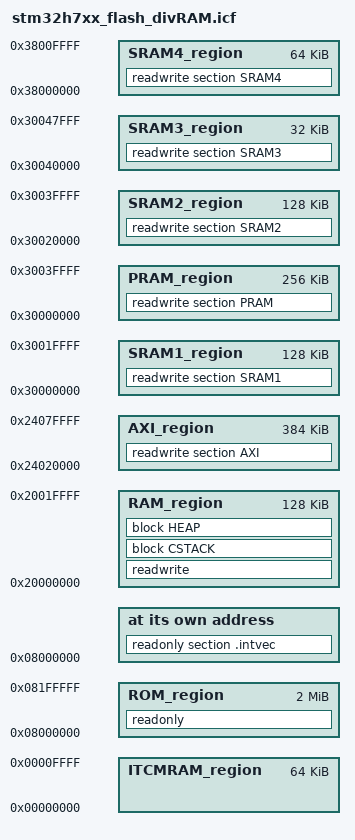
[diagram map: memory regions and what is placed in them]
/*###ICF### Section handled by ICF editor, don't touch! ****/
/*-Editor annotation file-*/
/* IcfEditorFile="$TOOLKIT_DIR$\config\ide\IcfEditor\cortex_v1_0.xml" */
/*-Specials-*/
define symbol __ICFEDIT_intvec_start__ = 0x08000000;
/*-Memory Regions-*/
define symbol __ICFEDIT_region_ROM_start__     = 0x08000000;
define symbol __ICFEDIT_region_ROM_end__       = 0x081FFFFF;
define symbol __ICFEDIT_region_RAM_start__     = 0x20000000;
define symbol __ICFEDIT_region_RAM_end__       = 0x2001FFFF;
define symbol __ICFEDIT_region_ITCMRAM_start__ = 0x00000000;
define symbol __ICFEDIT_region_ITCMRAM_end__   = 0x0000FFFF;
/*-Sizes-*/
define symbol __ICFEDIT_size_cstack__ = 0x400;
define symbol __ICFEDIT_size_heap__   = 0x200;
/**** End of ICF editor section. ###ICF###*/

define symbol __region_SRAM1_start__ = 0x30000000;
define symbol __region_SRAM1_end__   = 0x3001FFFF;
define symbol __region_SRAM2_start__ = 0x30020000;
define symbol __region_SRAM2_end__   = 0x3003FFFF;
define symbol __region_SRAM3_start__ = 0x30040000;
define symbol __region_SRAM3_end__   = 0x30047FFF;
define symbol __region_SRAM4_start__ = 0x38000000;
define symbol __region_SRAM4_end__   = 0x3800FFFF;
define symbol __region_AXI_start__   = 0x24020000;
define symbol __region_AXI_end__     = 0x2407FFFF;

define memory mem with size = 4G;
define region ROM_region      = mem:[from __ICFEDIT_region_ROM_start__   to __ICFEDIT_region_ROM_end__];
define region RAM_region      = mem:[from __ICFEDIT_region_RAM_start__   to __ICFEDIT_region_RAM_end__];
define region ITCMRAM_region  = mem:[from __ICFEDIT_region_ITCMRAM_start__ to __ICFEDIT_region_ITCMRAM_end__];
define region SRAM1_region    = mem:[from __region_SRAM1_start__ to __region_SRAM1_end__];
define region SRAM2_region    = mem:[from __region_SRAM2_start__ to __region_SRAM2_end__];
define region SRAM3_region    = mem:[from __region_SRAM3_start__ to __region_SRAM3_end__];
define region SRAM4_region    = mem:[from __region_SRAM4_start__ to __region_SRAM4_end__];
define region AXI_region      = mem:[from __region_AXI_start__ to __region_AXI_end__];
define region PRAM_region     = mem:[from __region_SRAM1_start__ to __region_SRAM2_end__];

define block CSTACK    with alignment = 8, size = __ICFEDIT_size_cstack__   { };
define block HEAP      with alignment = 8, size = __ICFEDIT_size_heap__     { };

initialize by copy { readwrite };
do not initialize  { section .noinit };

place at address mem:__ICFEDIT_intvec_start__ { readonly section .intvec };

place in ROM_region   { readonly };
place in RAM_region   { readwrite,
                        block CSTACK, block HEAP };
place in SRAM1_region { readwrite section SRAM1 };
place in SRAM2_region { readwrite section SRAM2 };
place in SRAM3_region { readwrite section SRAM3 };
place in SRAM4_region { readwrite section SRAM4 };
/*place in AXI_region { readwrite section AXI, block HEAP };*/
place in AXI_region { readwrite section AXI };
place in PRAM_region { readwrite section PRAM };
